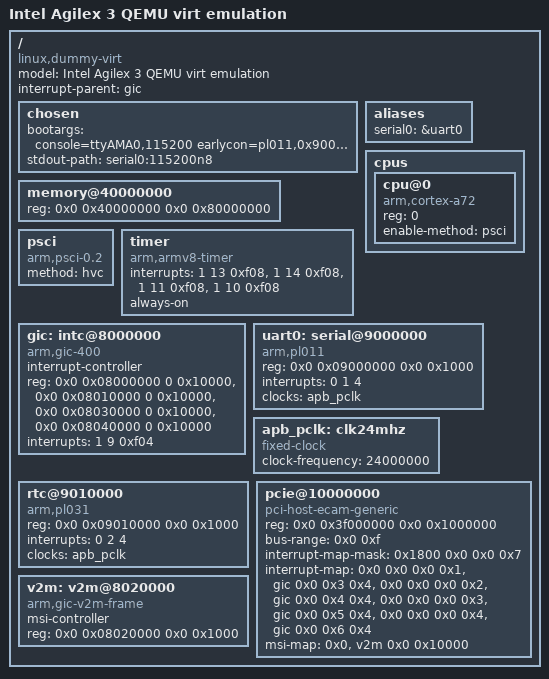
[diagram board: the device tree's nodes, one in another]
/*
 * Device Tree for Agilex 3 QEMU virt ARM64 emulation
 * Based on QEMU virt machine for ARM64
 */

/dts-v1/;

/ {
	model = "Intel Agilex 3 QEMU virt emulation";
	compatible = "linux,dummy-virt";
	interrupt-parent = <&gic>;
	#address-cells = <2>;
	#size-cells = <2>;

	chosen {
		bootargs = "console=ttyAMA0,115200 earlycon=pl011,0x9000000";
		stdout-path = "serial0:115200n8";
	};

	aliases {
		serial0 = &uart0;
	};

	memory@40000000 {
		device_type = "memory";
		reg = <0x0 0x40000000 0x0 0x80000000>; // 2GB starting at 1GB
	};

	cpus {
		#address-cells = <1>;
		#size-cells = <0>;

		cpu@0 {
			device_type = "cpu";
			compatible = "arm,cortex-a72";
			reg = <0>;
			enable-method = "psci";
		};
	};

	psci {
		compatible = "arm,psci-0.2";
		method = "hvc";
	};

	timer {
		compatible = "arm,armv8-timer";
		interrupts = <1 13 0xf08>,
			     <1 14 0xf08>,
			     <1 11 0xf08>,
			     <1 10 0xf08>;
		always-on;
	};

	gic: intc@8000000 {
		compatible = "arm,gic-400";
		#interrupt-cells = <3>;
		#address-cells = <0>;
		interrupt-controller;
		reg = <0x0 0x08000000 0 0x10000>,
		      <0x0 0x08010000 0 0x10000>,
		      <0x0 0x08030000 0 0x10000>,
		      <0x0 0x08040000 0 0x10000>;
		interrupts = <1 9 0xf04>;
	};

	uart0: serial@9000000 {
		compatible = "arm,pl011", "arm,primecell";
		reg = <0x0 0x09000000 0x0 0x1000>;
		interrupts = <0 1 4>;
		clocks = <&apb_pclk>;
		clock-names = "apb_pclk";
	};

	apb_pclk: clk24mhz {
		#clock-cells = <0>;
		compatible = "fixed-clock";
		clock-frequency = <24000000>;
	};

	rtc@9010000 {
		compatible = "arm,pl031", "arm,primecell";
		reg = <0x0 0x09010000 0x0 0x1000>;
		interrupts = <0 2 4>;
		clocks = <&apb_pclk>;
		clock-names = "apb_pclk";
	};

	pcie@10000000 {
		compatible = "pci-host-ecam-generic";
		device_type = "pci";
		#address-cells = <3>;
		#size-cells = <2>;
		#interrupt-cells = <1>;
		reg = <0x0 0x3f000000 0x0 0x1000000>;
		ranges = <0x1000000 0x0 0x0 0x0 0x3eff0000 0x0 0x10000>,
			 <0x2000000 0x0 0x10000000 0x0 0x10000000 0x0 0x2eff0000>;
		bus-range = <0x0 0xf>;
		interrupt-map-mask = <0x1800 0x0 0x0 0x7>;
		interrupt-map = <0x0 0x0 0x0 0x1 &gic 0x0 0x3 0x4>,
				<0x0 0x0 0x0 0x2 &gic 0x0 0x4 0x4>,
				<0x0 0x0 0x0 0x3 &gic 0x0 0x5 0x4>,
				<0x0 0x0 0x0 0x4 &gic 0x0 0x6 0x4>;
		msi-map = <0x0 &v2m 0x0 0x10000>;
	};

	v2m: v2m@8020000 {
		compatible = "arm,gic-v2m-frame";
		msi-controller;
		reg = <0x0 0x08020000 0x0 0x1000>;
	};
};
